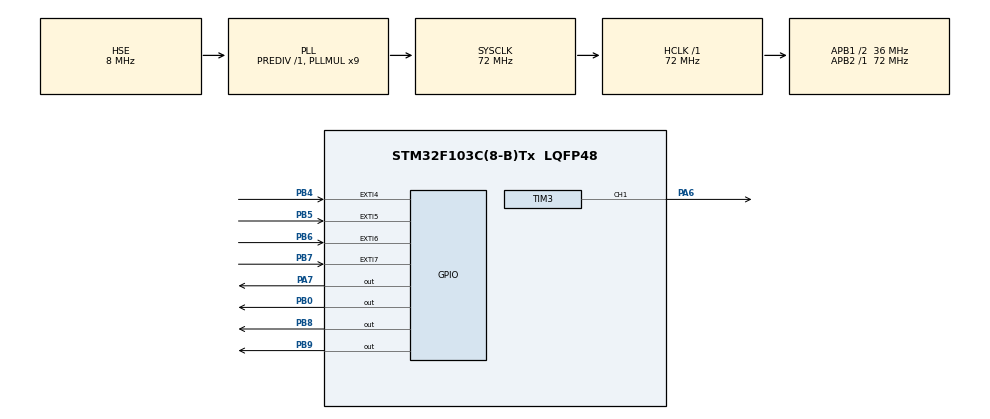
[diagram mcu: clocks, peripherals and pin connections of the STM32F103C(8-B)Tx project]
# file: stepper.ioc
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Mcu.Family=STM32F1
Mcu.Name=STM32F103C(8-B)Tx
Mcu.Package=LQFP48
NVIC.EXTI4_IRQn=true\:0\:0\:false\:false\:true\:true\:true\:true
NVIC.EXTI9_5_IRQn=true\:0\:0\:false\:false\:true\:true\:true\:true
NVIC.PriorityGroup=NVIC_PRIORITYGROUP_4
PA6.Signal=S_TIM3_CH1
PA7.Signal=GPIO_Output
PB0.Signal=GPIO_Output
PB4.GPIO_ModeDefaultEXTI=GPIO_MODE_IT_FALLING
PB4.GPIO_PuPd=GPIO_PULLUP
PB4.Signal=GPXTI4
PB5.GPIO_ModeDefaultEXTI=GPIO_MODE_IT_FALLING
PB5.GPIO_PuPd=GPIO_PULLUP
PB5.Signal=GPXTI5
PB6.GPIO_ModeDefaultEXTI=GPIO_MODE_IT_FALLING
PB6.GPIO_PuPd=GPIO_PULLUP
PB6.Signal=GPXTI6
PB7.GPIO_ModeDefaultEXTI=GPIO_MODE_IT_FALLING
PB7.GPIO_PuPd=GPIO_PULLUP
PB7.Signal=GPXTI7
PB8.GPIO_ModeDefaultOutputPP=GPIO_MODE_OUTPUT_OD
PB8.GPIO_PuPd=GPIO_NOPULL
PB8.Signal=GPIO_Output
PB9.GPIO_ModeDefaultOutputPP=GPIO_MODE_OUTPUT_OD
PB9.GPIO_PuPd=GPIO_NOPULL
PB9.Signal=GPIO_Output
PD0-OSC_IN.Mode=HSE-External-Oscillator
PD0-OSC_IN.Signal=RCC_OSC_IN
PD1-OSC_OUT.Mode=HSE-External-Oscillator
PD1-OSC_OUT.Signal=RCC_OSC_OUT
ProjectManager.HeapSize=0x200
ProjectManager.StackSize=0x400
ProjectManager.TargetToolchain=MDK-ARM V5.32
RCC.AHBFreq_Value=72000000
RCC.APB1CLKDivider=RCC_HCLK_DIV2
RCC.APB1Freq_Value=36000000
RCC.APB1TimFreq_Value=72000000
RCC.APB2Freq_Value=72000000
RCC.APB2TimFreq_Value=72000000
RCC.HCLKFreq_Value=72000000
RCC.PLLMUL=RCC_PLL_MUL9
RCC.PLLSourceVirtual=RCC_PLLSOURCE_HSE
RCC.SYSCLKFreq_VALUE=72000000
RCC.SYSCLKSource=RCC_SYSCLKSOURCE_PLLCLK
RCC.USBFreq_Value=72000000
SH.S_TIM3_CH1.0=TIM3_CH1,PWM Generation1 CH1
TIM3.Channel-PWM\ Generation1\ CH1=TIM_CHANNEL_1
TIM3.Prescaler=72
VP_SYS_VS_ND.Mode=No_Debug
board=custom

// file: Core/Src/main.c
/* USER CODE BEGIN Header */
/**
 ******************************************************************************
 * @file           : main.c
 * @brief          : Main program body
 ******************************************************************************
 * @attention
 *
 * Copyright (c) 2024 STMicroelectronics.
 * All rights reserved.
 *
 * This software is licensed under terms that can be found in the LICENSE file
 * in the root directory of this software component.
 * If no LICENSE file comes with this software, it is provided AS-IS.
 *
 ******************************************************************************
 */
/* USER CODE END Header */
#include "main.h"

/* USER CODE BEGIN Includes */
#include "stepper_motor.h"
#include "OLED.h"
#include "Menu.h"
#include "bsp_dwt.h"
/* USER CODE END Includes */

/* USER CODE BEGIN PM */
extern const uint8_t kunkun[13][512];
extern const uint8_t XpWallpaper[];
extern int run_time; // 转动时间单位ms
extern int start_time;
extern char motor_enable_flag;
extern int stop_time;
int timeline = 0;
static int8_t Current_Ver = -1;
extern int8_t ver;
char aaa1;
char aaa2;
double ccc1;
extern int smooth_time;
extern int Smooth;
extern TIM_HandleTypeDef stepper_tim;
extern uint32_t timclock;
extern int speed;
extern struct stepper_motor motor;
TIM_HandleTypeDef htim3;

void SystemClock_Config(void);
static void MX_GPIO_Init(void);
static void MX_TIM3_Init(void);

int main(void)
{

  /* MCU Configuration--------------------------------------------------------*/

  /* Reset of all peripherals, Initializes the Flash interface and the Systick. */
  HAL_Init();

  /* Configure the system clock */
  SystemClock_Config();

  /* Initialize all configured peripherals */
  MX_GPIO_Init();
  MX_TIM3_Init();
  /* USER CODE BEGIN 2 */
  // PWM初始化
  HAL_TIM_PWM_Init(&htim3);
  DWT_Init(72);

  // OLED屏幕初始化
  OLED_Init();

  // 步进电机初始化
  stepper_init();

  while (1)
  {
    timeline = DWT_GetTimeline_ms();
    if (motor_enable_flag)
    {
      if ((start_time + run_time) < (timeline))  //只要当前时间超出 开跑时刻和时间 就执行
      {
        if ((start_time + run_time + stop_time) < (timeline))//当前时间超出 开跑时刻和时间 停止时刻时间  就重置
          start_time = timeline;
        else  //超出开跑时间，但是在停止时间内
        {
          motor_disable();

					smooth_time = DWT_GetTimeline_ms();
					motor.open_flag = ON;
        }

        // 究极屎山
        if (motor.ver == Foreward) // 当电机转向突变
        {

          if (ver != -1)
          {

            if (Current_Ver == ver)
            {
              HAL_GPIO_WritePin(GPIOA, GPIO_PIN_7, 1 ^ HAL_GPIO_ReadPin(GPIOA, GPIO_PIN_7));
							smooth_time = DWT_GetTimeline_ms();
							motor.open_flag = ON;
              Current_Ver = 0;
            }
            else
            {
              Current_Ver++;
            }
          }
          if (Current_Ver == -1)
            Current_Ver = 0;
        }

        motor.ver = Reversal;
        // 究极屎山
      }
      else
      {
        motor_enable();

        // 究极屎山
        if (motor.ver == Reversal) // 当电机转向突变
        {
          motor.ver = Reversal;
        }
        motor.ver = Foreward;
        // 究极屎山
      }

      if (motor.open_flag == ON)
      {
        if ((smooth_time + Smooth) < DWT_GetTimeline_ms())
        {
           motor.open_flag = OFF;
          __HAL_TIM_SET_AUTORELOAD(&stepper_tim, (double)GET_TIM_F / (double)RAD2PWM(speed));
        }
        else
        {
         ccc1 = ((double)(DWT_GetTimeline_ms() - (float)smooth_time));
					__HAL_TIM_SET_AUTORELOAD(&stepper_tim, ((double)GET_TIM_F / (double)RAD2PWM(speed)) * (double)((DWT_GetTimeline_ms() - (double)smooth_time) / 100.0));
        }
      }

    }
    else
      motor_disable();
    step_run();
    // Delay_ms(1000);
    OLED_Clear();

    Menu_ShowWallpaper(XpWallpaper);

    // Menu_Showkunkun();
    //		OLED_ShowImage(0,0,64, 64, kunkun[count++/10]);

    //		OLED_ShowImage(64,0,64, 64, kunkun[count++/10]);
    //		count %= 130;
    if (Menu_Start(0) == 0) // 如果初始化完成了
    {
      if (Menu_EnterEvent())
      {
        Menu_Start(1);
      }
      if (Menu_BackEvent())
      {
        // Power_Off();
      }
    }
    OLED_Update();
		HAL_Delay(1);
  }
  //       +HAL_Delay(1000);

}

void SystemClock_Config(void)
{
  RCC_OscInitTypeDef RCC_OscInitStruct = {0};
  RCC_ClkInitTypeDef RCC_ClkInitStruct = {0};

  /** Initializes the RCC Oscillators according to the specified parameters
   * in the RCC_OscInitTypeDef structure.
   */
  RCC_OscInitStruct.OscillatorType = RCC_OSCILLATORTYPE_HSE;
  RCC_OscInitStruct.HSEState = RCC_HSE_ON;
  RCC_OscInitStruct.HSEPredivValue = RCC_HSE_PREDIV_DIV1;
  RCC_OscInitStruct.HSIState = RCC_HSI_ON;
  RCC_OscInitStruct.PLL.PLLState = RCC_PLL_ON;
  RCC_OscInitStruct.PLL.PLLSource = RCC_PLLSOURCE_HSE;
  RCC_OscInitStruct.PLL.PLLMUL = RCC_PLL_MUL9;
  if (HAL_RCC_OscConfig(&RCC_OscInitStruct) != HAL_OK)
  {
    Error_Handler();
  }

  /** Initializes the CPU, AHB and APB buses clocks
   */
  RCC_ClkInitStruct.ClockType = RCC_CLOCKTYPE_HCLK | RCC_CLOCKTYPE_SYSCLK | RCC_CLOCKTYPE_PCLK1 | RCC_CLOCKTYPE_PCLK2;
  RCC_ClkInitStruct.SYSCLKSource = RCC_SYSCLKSOURCE_PLLCLK;
  RCC_ClkInitStruct.AHBCLKDivider = RCC_SYSCLK_DIV1;
  RCC_ClkInitStruct.APB1CLKDivider = RCC_HCLK_DIV2;
  RCC_ClkInitStruct.APB2CLKDivider = RCC_HCLK_DIV1;

  if (HAL_RCC_ClockConfig(&RCC_ClkInitStruct, FLASH_LATENCY_2) != HAL_OK)
  {
    Error_Handler();
  }
}

static void MX_TIM3_Init(void)
{

  TIM_MasterConfigTypeDef sMasterConfig = {0};
  TIM_OC_InitTypeDef sConfigOC = {0};

  htim3.Instance = TIM3;
  htim3.Init.Prescaler = 72;
  htim3.Init.CounterMode = TIM_COUNTERMODE_UP;
  htim3.Init.Period = 65535;
  htim3.Init.ClockDivision = TIM_CLOCKDIVISION_DIV1;
  htim3.Init.AutoReloadPreload = TIM_AUTORELOAD_PRELOAD_DISABLE;
  if (HAL_TIM_PWM_Init(&htim3) != HAL_OK)
  {
    Error_Handler();
  }
  sMasterConfig.MasterOutputTrigger = TIM_TRGO_RESET;
  sMasterConfig.MasterSlaveMode = TIM_MASTERSLAVEMODE_DISABLE;
  if (HAL_TIMEx_MasterConfigSynchronization(&htim3, &sMasterConfig) != HAL_OK)
  {
    Error_Handler();
  }
  sConfigOC.OCMode = TIM_OCMODE_PWM1;
  sConfigOC.Pulse = 0;
  sConfigOC.OCPolarity = TIM_OCPOLARITY_HIGH;
  sConfigOC.OCFastMode = TIM_OCFAST_DISABLE;
  if (HAL_TIM_PWM_ConfigChannel(&htim3, &sConfigOC, TIM_CHANNEL_1) != HAL_OK)
  {
    Error_Handler();
  }
  HAL_TIM_MspPostInit(&htim3);
}

static void MX_GPIO_Init(void)
{
  GPIO_InitTypeDef GPIO_InitStruct = {0};

  /* GPIO Ports Clock Enable */
  __HAL_RCC_GPIOD_CLK_ENABLE();
  __HAL_RCC_GPIOA_CLK_ENABLE();
  __HAL_RCC_GPIOB_CLK_ENABLE();

  /*Configure GPIO pin Output Level */
  HAL_GPIO_WritePin(GPIOA, GPIO_PIN_7, GPIO_PIN_RESET);

  /*Configure GPIO pin Output Level */
  HAL_GPIO_WritePin(GPIOB, GPIO_PIN_0 | GPIO_PIN_8 | GPIO_PIN_9, GPIO_PIN_RESET);

  /*Configure GPIO pin : PA7 */
  GPIO_InitStruct.Pin = GPIO_PIN_7;
  GPIO_InitStruct.Mode = GPIO_MODE_OUTPUT_PP;
  GPIO_InitStruct.Pull = GPIO_NOPULL;
  GPIO_InitStruct.Speed = GPIO_SPEED_FREQ_LOW;
  HAL_GPIO_Init(GPIOA, &GPIO_InitStruct);

  /*Configure GPIO pin : PB0 */
  GPIO_InitStruct.Pin = GPIO_PIN_0;
  GPIO_InitStruct.Mode = GPIO_MODE_OUTPUT_PP;
  GPIO_InitStruct.Pull = GPIO_NOPULL;
  GPIO_InitStruct.Speed = GPIO_SPEED_FREQ_LOW;
  HAL_GPIO_Init(GPIOB, &GPIO_InitStruct);

  /*Configure GPIO pins : PB4 PB5 PB6 PB7 */
  GPIO_InitStruct.Pin = GPIO_PIN_4 | GPIO_PIN_5 | GPIO_PIN_6 | GPIO_PIN_7;
  GPIO_InitStruct.Mode = GPIO_MODE_IT_FALLING;
  GPIO_InitStruct.Pull = GPIO_PULLUP;
  HAL_GPIO_Init(GPIOB, &GPIO_InitStruct);

  /*Configure GPIO pins : PB8 PB9 */
  GPIO_InitStruct.Pin = GPIO_PIN_8 | GPIO_PIN_9;
  GPIO_InitStruct.Mode = GPIO_MODE_OUTPUT_OD;
  GPIO_InitStruct.Pull = GPIO_NOPULL;
  GPIO_InitStruct.Speed = GPIO_SPEED_FREQ_LOW;
  HAL_GPIO_Init(GPIOB, &GPIO_InitStruct);

  /* EXTI interrupt init*/
  HAL_NVIC_SetPriority(EXTI4_IRQn, 0, 0);
  HAL_NVIC_EnableIRQ(EXTI4_IRQn);

  HAL_NVIC_SetPriority(EXTI9_5_IRQn, 0, 0);
  HAL_NVIC_EnableIRQ(EXTI9_5_IRQn);
}

void Error_Handler(void)
{
  __disable_irq();
  while (1)
  {
  }
}
